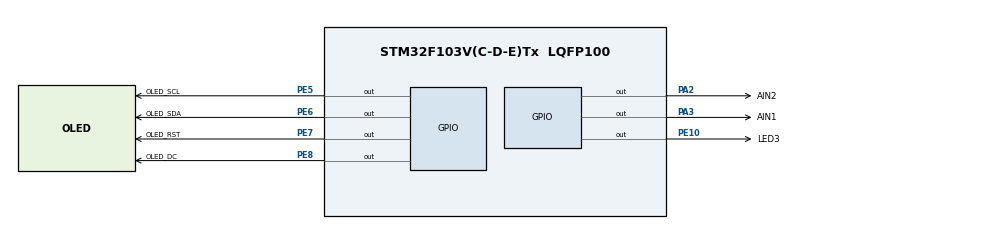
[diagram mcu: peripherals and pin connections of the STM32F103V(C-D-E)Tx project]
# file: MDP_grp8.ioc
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FREERTOS.Tasks01=defaultTask,24,128,StartDefaultTask,Default,NULL,Dynamic,NULL,NULL;ShowTask,8,128,show,Default,NULL,Dynamic,NULL,NULL;MotorTask,8,128,motors,Default,NULL,Dynamic,NULL,NULL
Mcu.Family=STM32F1
Mcu.Name=STM32F103V(C-D-E)Tx
Mcu.Package=LQFP100
NVIC.PriorityGroup=NVIC_PRIORITYGROUP_4
PA2.GPIO_Label=AIN2
PA2.GPIO_Speed=GPIO_SPEED_FREQ_HIGH
PA2.PinState=GPIO_PIN_RESET
PA2.Signal=GPIO_Output
PA3.GPIO_Label=AIN1
PA3.GPIO_Speed=GPIO_SPEED_FREQ_HIGH
PA3.Signal=GPIO_Output
PC6.GPIO_Label=PWM8
PC6.Signal=S_TIM8_CH1
PE10.GPIO_Label=LED3
PE10.Signal=GPIO_Output
PE5.GPIO_Label=OLED_SCL
PE5.Signal=GPIO_Output
PE6.GPIO_Label=OLED_SDA
PE6.Signal=GPIO_Output
PE7.GPIO_Label=OLED_RST
PE7.Signal=GPIO_Output
PE8.GPIO_Label=OLED_DC
PE8.Signal=GPIO_Output
ProjectManager.HeapSize=0x200
ProjectManager.StackSize=0x400
ProjectManager.TargetToolchain=STM32CubeIDE
RCC.APB1Freq_Value=8000000
RCC.APB2Freq_Value=8000000
SH.S_TIM8_CH1.0=TIM8_CH1
TIM8.Channel-PWM\ Generation1\ No\ Output=TIM_CHANNEL_1
TIM8.Period=7199
VP_FREERTOS_VS_CMSIS_V2.Mode=CMSIS_V2
VP_SYS_VS_ND.Mode=No_Debug
VP_TIM8_VS_ClockSourceINT.Mode=Internal
VP_TIM8_VS_no_output1.Mode=PWM Generation1 No Output
board=custom

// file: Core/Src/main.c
/* USER CODE BEGIN Header */
/**
  ******************************************************************************
  * @file           : main.c
  * @brief          : Main program body
  ******************************************************************************
  * @attention
  *
  * <h2><center>&copy; Copyright (c) 2021 STMicroelectronics.
  * All rights reserved.</center></h2>
  *
  * This software component is licensed by ST under BSD 3-Clause license,
  * the "License"; You may not use this file except in compliance with the
  * License. You may obtain a copy of the License at:
  *                        opensource.org/licenses/BSD-3-Clause
  *
  ******************************************************************************
  */
/* USER CODE END Header */
#include "main.h"
#include "cmsis_os.h"

/* USER CODE BEGIN Includes */
#include "oled.h"
/* USER CODE END Includes */

TIM_HandleTypeDef htim8;

/* Definitions for defaultTask */
osThreadId_t defaultTaskHandle;
const osThreadAttr_t defaultTask_attributes = {
  .name = "defaultTask",
  .stack_size = 128 * 4,
  .priority = (osPriority_t) osPriorityNormal,
};
/* Definitions for ShowTask */
osThreadId_t ShowTaskHandle;
const osThreadAttr_t ShowTask_attributes = {
  .name = "ShowTask",
  .stack_size = 128 * 4,
  .priority = (osPriority_t) osPriorityLow,
};
/* Definitions for MotorTask */
osThreadId_t MotorTaskHandle;
const osThreadAttr_t MotorTask_attributes = {
  .name = "MotorTask",
  .stack_size = 128 * 4,
  .priority = (osPriority_t) osPriorityLow,
};

void SystemClock_Config(void);
static void MX_GPIO_Init(void);
static void MX_TIM8_Init(void);
void StartDefaultTask(void *argument);
void show(void *argument);
void motors(void *argument);

int main(void)
{

  /* MCU Configuration--------------------------------------------------------*/

  /* Reset of all peripherals, Initializes the Flash interface and the Systick. */
  HAL_Init();

  /* Configure the system clock */
  SystemClock_Config();

  /* Initialize all configured peripherals */
  MX_GPIO_Init();
  MX_TIM8_Init();

  /* Init scheduler */
  osKernelInitialize();

  /* Create the thread(s) */
  /* creation of defaultTask */
  defaultTaskHandle = osThreadNew(StartDefaultTask, NULL, &defaultTask_attributes);

  /* creation of ShowTask */
  ShowTaskHandle = osThreadNew(show, NULL, &ShowTask_attributes);

  /* creation of MotorTask */
  MotorTaskHandle = osThreadNew(motors, NULL, &MotorTask_attributes);

  /* Start scheduler */
  osKernelStart();

  /* We should never get here as control is now taken by the scheduler */
  /* Infinite loop */
  while (1)
  {

  }
}

void SystemClock_Config(void)
{
  RCC_OscInitTypeDef RCC_OscInitStruct = {0};
  RCC_ClkInitTypeDef RCC_ClkInitStruct = {0};

  /** Initializes the RCC Oscillators according to the specified parameters
  * in the RCC_OscInitTypeDef structure.
  */
  RCC_OscInitStruct.OscillatorType = RCC_OSCILLATORTYPE_HSI;
  RCC_OscInitStruct.HSIState = RCC_HSI_ON;
  RCC_OscInitStruct.HSICalibrationValue = RCC_HSICALIBRATION_DEFAULT;
  RCC_OscInitStruct.PLL.PLLState = RCC_PLL_NONE;
  if (HAL_RCC_OscConfig(&RCC_OscInitStruct) != HAL_OK)
  {
    Error_Handler();
  }
  /** Initializes the CPU, AHB and APB buses clocks
  */
  RCC_ClkInitStruct.ClockType = RCC_CLOCKTYPE_HCLK|RCC_CLOCKTYPE_SYSCLK
                              |RCC_CLOCKTYPE_PCLK1|RCC_CLOCKTYPE_PCLK2;
  RCC_ClkInitStruct.SYSCLKSource = RCC_SYSCLKSOURCE_HSI;
  RCC_ClkInitStruct.AHBCLKDivider = RCC_SYSCLK_DIV1;
  RCC_ClkInitStruct.APB1CLKDivider = RCC_HCLK_DIV1;
  RCC_ClkInitStruct.APB2CLKDivider = RCC_HCLK_DIV1;

  if (HAL_RCC_ClockConfig(&RCC_ClkInitStruct, FLASH_LATENCY_0) != HAL_OK)
  {
    Error_Handler();
  }
}

static void MX_TIM8_Init(void)
{

  TIM_ClockConfigTypeDef sClockSourceConfig = {0};
  TIM_MasterConfigTypeDef sMasterConfig = {0};
  TIM_OC_InitTypeDef sConfigOC = {0};
  TIM_BreakDeadTimeConfigTypeDef sBreakDeadTimeConfig = {0};

  htim8.Instance = TIM8;
  htim8.Init.Prescaler = 0;
  htim8.Init.CounterMode = TIM_COUNTERMODE_UP;
  htim8.Init.Period = 7199;
  htim8.Init.ClockDivision = TIM_CLOCKDIVISION_DIV1;
  htim8.Init.RepetitionCounter = 0;
  htim8.Init.AutoReloadPreload = TIM_AUTORELOAD_PRELOAD_DISABLE;
  if (HAL_TIM_Base_Init(&htim8) != HAL_OK)
  {
    Error_Handler();
  }
  sClockSourceConfig.ClockSource = TIM_CLOCKSOURCE_INTERNAL;
  if (HAL_TIM_ConfigClockSource(&htim8, &sClockSourceConfig) != HAL_OK)
  {
    Error_Handler();
  }
  if (HAL_TIM_PWM_Init(&htim8) != HAL_OK)
  {
    Error_Handler();
  }
  sMasterConfig.MasterOutputTrigger = TIM_TRGO_RESET;
  sMasterConfig.MasterSlaveMode = TIM_MASTERSLAVEMODE_DISABLE;
  if (HAL_TIMEx_MasterConfigSynchronization(&htim8, &sMasterConfig) != HAL_OK)
  {
    Error_Handler();
  }
  sConfigOC.OCMode = TIM_OCMODE_PWM1;
  sConfigOC.Pulse = 0;
  sConfigOC.OCPolarity = TIM_OCPOLARITY_HIGH;
  sConfigOC.OCNPolarity = TIM_OCNPOLARITY_HIGH;
  sConfigOC.OCFastMode = TIM_OCFAST_DISABLE;
  sConfigOC.OCIdleState = TIM_OCIDLESTATE_RESET;
  sConfigOC.OCNIdleState = TIM_OCNIDLESTATE_RESET;
  if (HAL_TIM_PWM_ConfigChannel(&htim8, &sConfigOC, TIM_CHANNEL_1) != HAL_OK)
  {
    Error_Handler();
  }
  sBreakDeadTimeConfig.OffStateRunMode = TIM_OSSR_DISABLE;
  sBreakDeadTimeConfig.OffStateIDLEMode = TIM_OSSI_DISABLE;
  sBreakDeadTimeConfig.LockLevel = TIM_LOCKLEVEL_OFF;
  sBreakDeadTimeConfig.DeadTime = 0;
  sBreakDeadTimeConfig.BreakState = TIM_BREAK_DISABLE;
  sBreakDeadTimeConfig.BreakPolarity = TIM_BREAKPOLARITY_HIGH;
  sBreakDeadTimeConfig.AutomaticOutput = TIM_AUTOMATICOUTPUT_DISABLE;
  if (HAL_TIMEx_ConfigBreakDeadTime(&htim8, &sBreakDeadTimeConfig) != HAL_OK)
  {
    Error_Handler();
  }

}

static void MX_GPIO_Init(void)
{
  GPIO_InitTypeDef GPIO_InitStruct = {0};

  /* GPIO Ports Clock Enable */
  __HAL_RCC_GPIOE_CLK_ENABLE();
  __HAL_RCC_GPIOA_CLK_ENABLE();
  __HAL_RCC_GPIOC_CLK_ENABLE();

  /*Configure GPIO pin Output Level */
  HAL_GPIO_WritePin(GPIOE, OLED_SCL_Pin|OLED_SDA_Pin|OLED_RST_Pin|OLED_DC_Pin
                          |LED3_Pin, GPIO_PIN_RESET);

  /*Configure GPIO pin Output Level */
  HAL_GPIO_WritePin(GPIOA, AIN2_Pin|AIN1_Pin, GPIO_PIN_RESET);

  /*Configure GPIO pins : OLED_SCL_Pin OLED_SDA_Pin OLED_RST_Pin OLED_DC_Pin
                           LED3_Pin */
  GPIO_InitStruct.Pin = OLED_SCL_Pin|OLED_SDA_Pin|OLED_RST_Pin|OLED_DC_Pin
                          |LED3_Pin;
  GPIO_InitStruct.Mode = GPIO_MODE_OUTPUT_PP;
  GPIO_InitStruct.Pull = GPIO_NOPULL;
  GPIO_InitStruct.Speed = GPIO_SPEED_FREQ_LOW;
  HAL_GPIO_Init(GPIOE, &GPIO_InitStruct);

  /*Configure GPIO pins : AIN2_Pin AIN1_Pin */
  GPIO_InitStruct.Pin = AIN2_Pin|AIN1_Pin;
  GPIO_InitStruct.Mode = GPIO_MODE_OUTPUT_PP;
  GPIO_InitStruct.Pull = GPIO_NOPULL;
  GPIO_InitStruct.Speed = GPIO_SPEED_FREQ_HIGH;
  HAL_GPIO_Init(GPIOA, &GPIO_InitStruct);

}

void StartDefaultTask(void *argument)
{
  /* USER CODE BEGIN 5 */
  /* Infinite loop */
  for(;;)
  {
	  HAL_GPIO_TogglePin(LED3_GPIO_Port, LED3_Pin);
	  osDelay(5000);
  }
  /* USER CODE END 5 */
}

void show(void *argument)
{
  /* USER CODE BEGIN show */
	uint8_t hello[20]="Hello World!\0";
  /* Infinite loop */
  for(;;)
  {
	  OLED_ShowString(10,10,hello);
	  OLED_Refresh_Gram();
    osDelay(1000);
  }
  /* USER CODE END show */
}

void motors(void *argument)
{
  for(;;)
  {
    osDelay(1);
  }
}

void Error_Handler(void)
{
  __disable_irq();
  while (1)
  {
  }
}

/************************ (C) COPYRIGHT STMicroelectronics *****END OF FILE****/
